# CS__Clock_System_2 register map
Vendor: Texas Instruments
Peripheral module from a debugger description file (folder msp430).
Registers are 16-bit, read-write, reset 0x0 unless marked. A register's access mark holds for its fields unless they carry their own. Offsets are as the file gives them; lines under a group give offsets from that group; [hi:lo] are bit positions; {n}, {i} and the like mark numbered series; 'fields as' and 'values as' point back to an identical list; <NAME> marks a mode.

## CS_Clock_System
0x160 CSCTL0 access not given reset not defined — CS Control Register 0
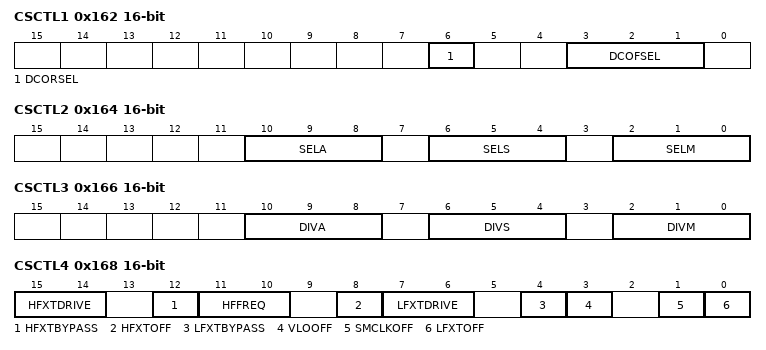
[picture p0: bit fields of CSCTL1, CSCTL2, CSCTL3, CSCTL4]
0x162 CSCTL1 — CS Control Register 1
  [6] DCORSEL — DCO range select.
  [3:1] DCOFSEL — DCO frequency select Bit: 0
    {v}=DCO frequency select: {v} (v=0..7)
0x164 CSCTL2 — CS Control Register 2
  [10:8] SELA — ACLK Source Select Bit: 0
    {v}=ACLK Source Select {v} (v=0..7)
  [6:4] SELS — SMCLK Source Select Bit: 0
    {v}=SMCLK Source Select {v} (v=0..7)
  [2:0] SELM — MCLK Source Select Bit: 0
    {v}=MCLK Source Select {v} (v=0..7)
0x166 CSCTL3 — CS Control Register 3
  [10:8] DIVA — ACLK Divider Bit: 0
    {v}=ACLK Source Divider {v} (v=0..5)
  [6:4] DIVS — SMCLK Divider Bit: 0
    {v}=SMCLK Source Divider {v} (v=0..5)
  [2:0] DIVM — MCLK Divider Bit: 0
    {v}=MCLK Source Divider {v} (v=0..5)
0x168 CSCTL4 — CS Control Register 4
  [15:14] HFXTDRIVE — HFXT Drive Level mode Bit 0
    {v}=HFXT Drive Level mode: {v} (v=0..3)
  [12] HFXTBYPASS — HFXT bypass mode : 0: internal 1:sourced from external pin
  [11:10] HFFREQ — HFXT frequency selection Bit 1
    {v}=HFXT frequency selection: {v} (v=0..3)
  [8] HFXTOFF — High Frequency Oscillator disable
  [7:6] LFXTDRIVE — LFXT Drive Level mode Bit 0
    {v}=LFXT Drive Level mode: {v} (v=0..3)
  [4] LFXTBYPASS — LFXT bypass mode : 0: internal 1:sourced from external pin
  [3] VLOOFF
  [1] SMCLKOFF
  [0] LFXTOFF — Low Frequency Oscillator (LFXT) disable
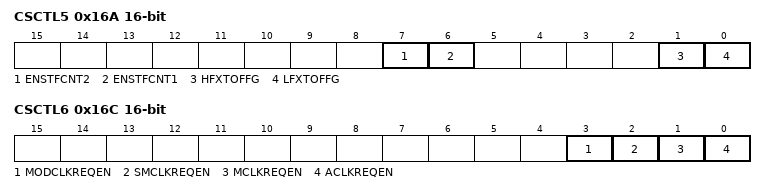
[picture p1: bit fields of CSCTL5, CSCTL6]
0x16A CSCTL5 — CS Control Register 5
  [7] ENSTFCNT2 — Enable start counter for XT2
  [6] ENSTFCNT1 — Enable start counter for XT1
  [1] HFXTOFFG — HFXT High Frequency Oscillator Fault Flag
  [0] LFXTOFFG — LFXT Low Frequency Oscillator Fault Flag
0x16C CSCTL6 — CS Control Register 6
  [3] MODCLKREQEN — MODOSC Clock Request Enable
  [2] SMCLKREQEN — SMCLK Clock Request Enable
  [1] MCLKREQEN — MCLK Clock Request Enable
  [0] ACLKREQEN — ACLK Clock Request Enable
